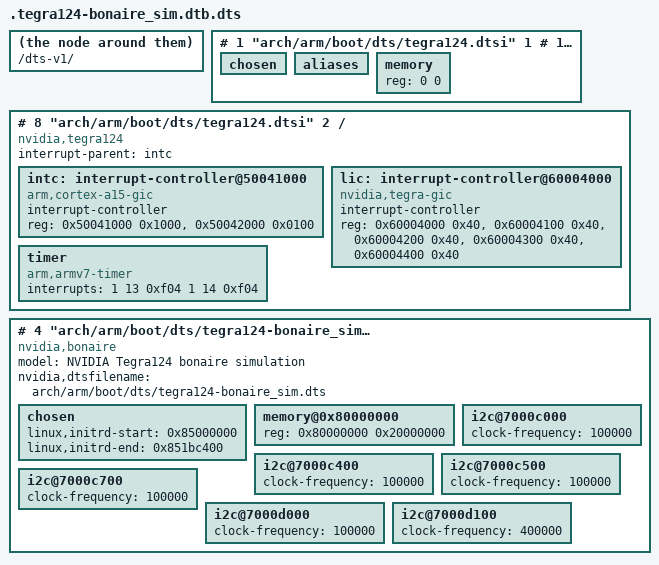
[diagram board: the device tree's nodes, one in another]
# 1 "arch/arm/boot/dts/tegra124-bonaire_sim.dts"
# 1 "<built-in>"
# 1 "<command-line>"
# 1 "arch/arm/boot/dts/tegra124-bonaire_sim.dts"
/dts-v1/;

# 1 "arch/arm/boot/dts/tegra124.dtsi" 1
# 1 "/usr/src/kernel/arch/arm/boot/dts/include/dt-bindings/gpio/tegra-gpio.h" 1
# 13 "/usr/src/kernel/arch/arm/boot/dts/include/dt-bindings/gpio/tegra-gpio.h"
# 1 "/usr/src/kernel/arch/arm/boot/dts/include/dt-bindings/gpio/gpio.h" 1
# 14 "/usr/src/kernel/arch/arm/boot/dts/include/dt-bindings/gpio/tegra-gpio.h" 2
# 2 "arch/arm/boot/dts/tegra124.dtsi" 2
# 1 "/usr/src/kernel/arch/arm/boot/dts/include/dt-bindings/input/input.h" 1
# 3 "arch/arm/boot/dts/tegra124.dtsi" 2
# 1 "/usr/src/kernel/arch/arm/boot/dts/include/dt-bindings/interrupt-controller/arm-gic.h" 1







# 1 "/usr/src/kernel/arch/arm/boot/dts/include/dt-bindings/interrupt-controller/irq.h" 1
# 9 "/usr/src/kernel/arch/arm/boot/dts/include/dt-bindings/interrupt-controller/arm-gic.h" 2
# 4 "arch/arm/boot/dts/tegra124.dtsi" 2

/include/ "tegra124-soc.dtsi"

# 1 "arch/arm/boot/dts/skeleton.dtsi" 1






/ {
 #address-cells = <1>;
 #size-cells = <1>;
 chosen { };
 aliases { };
 memory { device_type = "memory"; reg = <0 0>; };
};
# 8 "arch/arm/boot/dts/tegra124.dtsi" 2

/ {
 compatible = "nvidia,tegra124";
 interrupt-parent = <&intc>;
 #address-cells = <1>;
 #size-cells = <1>;

 intc: interrupt-controller@50041000 {
  compatible = "arm,cortex-a15-gic";
  interrupt-controller;
  #interrupt-cells = <3>;
  reg = <0x50041000 0x1000>,
        <0x50042000 0x0100>;
 };

 lic: interrupt-controller@60004000 {
  compatible = "nvidia,tegra-gic";
  interrupt-controller;
  reg = <0x60004000 0x40>,
        <0x60004100 0x40>,
        <0x60004200 0x40>,
        <0x60004300 0x40>,
        <0x60004400 0x40>;
        };

 timer {
  compatible = "arm,armv7-timer";
  interrupts = <1 13 0xf04
         1 14 0xf04>;
 };
};
# 4 "arch/arm/boot/dts/tegra124-bonaire_sim.dts" 2

/ {
 model = "NVIDIA Tegra124 bonaire simulation";
 compatible = "nvidia,bonaire", "nvidia,tegra124";
 nvidia,dtsfilename = "arch/arm/boot/dts/tegra124-bonaire_sim.dts";


 chosen {
  linux,initrd-start = <0x85000000>;
  linux,initrd-end = <0x851bc400>;
 };

 memory@0x80000000 {
  #address-cells = <2>;
  #size-cells = <1>;
  device_type = "memory";
  reg = <0x80000000 0x20000000>;
 };

 i2c@7000c000 {
  status = "okay";
  clock-frequency = <100000>;
 };

 i2c@7000c400 {
  status = "okay";
  clock-frequency = <100000>;
 };

 i2c@7000c500 {
  status = "okay";
  clock-frequency = <100000>;
 };

 i2c@7000c700 {
  status = "okay";
  clock-frequency = <100000>;
 };

 i2c@7000d000 {
  status = "okay";
  clock-frequency = <100000>;
 };

 i2c@7000d100 {
  status = "okay";
  clock-frequency = <400000>;
 };
};
